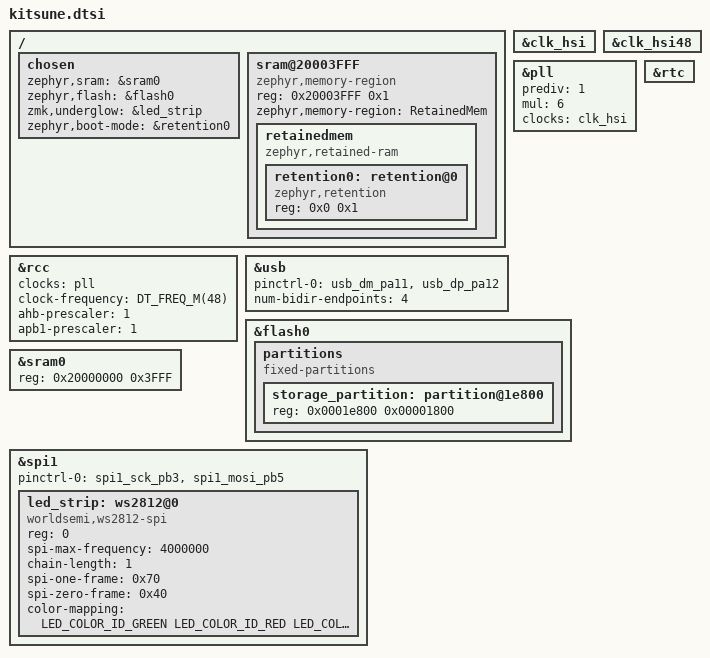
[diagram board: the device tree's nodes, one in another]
/dts-v1/;
#include <st/f0/stm32f072Xb.dtsi>
#include <st/f0/stm32f072c(8-b)tx-pinctrl.dtsi>

/ {
    chosen {
        zephyr,sram = &sram0;
        zephyr,flash = &flash0;
        zmk,underglow = &led_strip;
    };
};

&clk_hsi {
    status = "okay";
};

&clk_hsi48 {
    status = "okay";
};

&pll {
    prediv = <1>;
    mul = <6>;
    clocks = <&clk_hsi>;
    status = "okay";
};

&rcc {
    clocks = <&pll>;
    clock-frequency = <DT_FREQ_M(48)>;
    ahb-prescaler = <1>;
    apb1-prescaler = <1>;
};

&rtc {
    status = "okay";
};

zephyr_udc0: &usb {
    status = "okay";
    pinctrl-0 = <&usb_dm_pa11 &usb_dp_pa12>;
    pinctrl-names = "default";

    // Overridden to lower RAM usage.
    num-bidir-endpoints = <4>;
};

&flash0 {
    /*
     * For more information, see:
     * http://docs.zephyrproject.org/latest/guides/dts/index.html#flash-partitions
     */
    partitions {
        compatible = "fixed-partitions";
        #address-cells = <1>;
        #size-cells = <1>;

        /* Set 6Kb of storage at the end of the 128Kb of flash */
        storage_partition: partition@1e800 {
            reg = <0x0001e800 0x00001800>;
        };
    };
};

/ {
    sram@20003FFF {
        compatible = "zephyr,memory-region", "mmio-sram";
        reg = <0x20003FFF 0x1>;
        zephyr,memory-region = "RetainedMem";
        status = "okay";

        retainedmem {
            compatible = "zephyr,retained-ram";
            status = "okay";
            #address-cells = <1>;
            #size-cells = <1>;

            retention0: retention@0 {
                compatible = "zephyr,retention";
                status = "okay";
                reg = <0x0 0x1>;
            };
        };
    };

    chosen {
        zephyr,boot-mode = &retention0;
    };
};

/* Reduce SRAM0 usage by 1 byte to account for non-init area */
&sram0 {
    reg = <0x20000000 0x3FFF>;
};

&spi1 {
    status = "okay";
    pinctrl-0 = <&spi1_sck_pb3 &spi1_mosi_pb5>;
    pinctrl-names = "default";

    led_strip: ws2812@0 {
        compatible = "worldsemi,ws2812-spi";

        /* SPI */
        reg = <0>; /* ignored, but necessary for SPI bindings */
        spi-max-frequency = <4000000>;

        /* WS2812 */
        chain-length = <1>;
        spi-one-frame = <0x70>;
        spi-zero-frame = <0x40>;

        color-mapping = <LED_COLOR_ID_GREEN
                         LED_COLOR_ID_RED
                         LED_COLOR_ID_BLUE>;
    };
};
